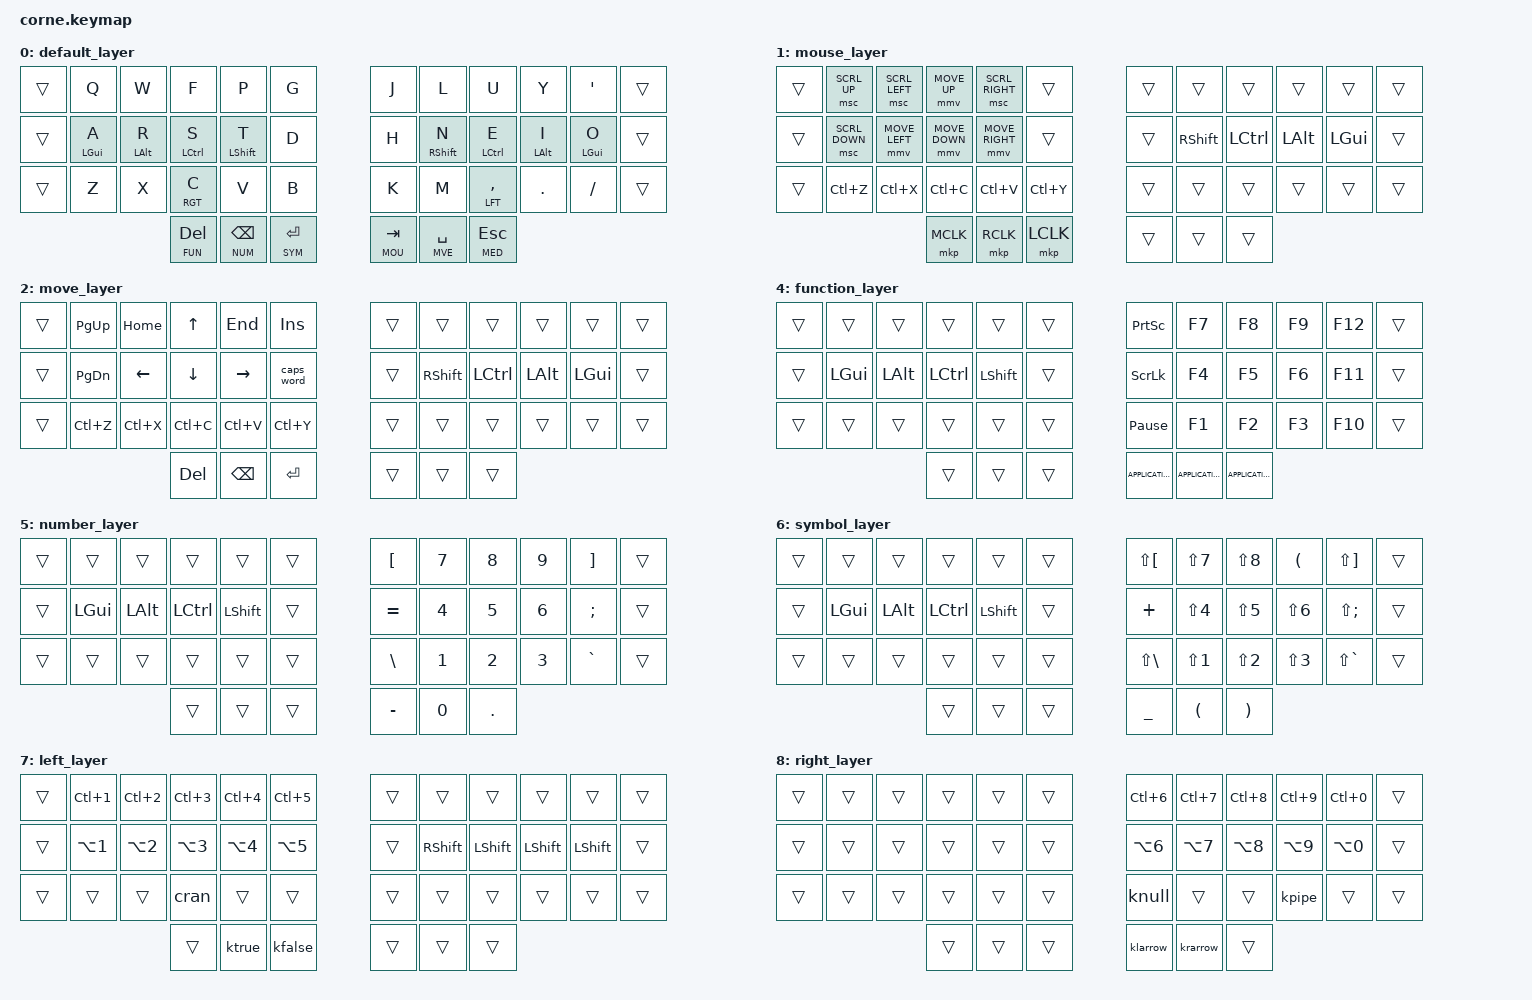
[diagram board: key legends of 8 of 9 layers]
#include <behaviors.dtsi>
#include <dt-bindings/zmk/keys.h>
#include <dt-bindings/zmk/bt.h>
#define _BT_SEL_KEYS_ &bt BT_SEL 0 &bt BT_SEL 1 &bt BT_SEL 2 &bt BT_SEL 3 &bt BT_CLR

#include <dt-bindings/zmk/mouse.h>

#include "../zmk-nodefree-config/helper.h"
#include "../zmk-nodefree-config/keypos_def/keypos_42keys.h"
//#include "../zmk-nodefree-config/international_chars/german.dtsi"

/* layer and key shortcuts */

#define XXX &none
#define ___ &trans

#define DEF 0 // layer shortcuts, must match order in which they are defined below
#define MOU 1 // mouse layer
#define MVE 2 // move layer
#define MED 3 // media layer
#define FUN 4 // function layer
#define NUM 5 // number layer
#define SYM 6 // symbols
#define LFT 7 // left extra
#define RGT 8 // right extra

/* custom behaviors */
// https://github.com/urob/zmk-config?tab=readme-ov-file#timeless-homerow-mods
#define KEYS_L LT0 LT1 LT2 LT3 LT4 LT5 LM0 LM1 LM2 LM3 LM4 LM5 LB0 LB1 LB2 LB3 LB4 LB5  // left-hand keys
#define KEYS_R RT0 RT1 RT2 RT3 RT4 RT5 RM0 RM1 RM2 RM3 RM4 RM5 RB0 RB1 RB2 RB3 RB4 RB5  // right-hand keys
#define THUMBS LH2 LH1 LH0 RH0 RH1 RH2                                      // thumb keys


// From https://github.com/urob/zmk-config/blob/main/config/mouse.dtsi
#define ZMK_MOUSE_DEFAULT_MOVE_VAL 1500  // 600
#define ZMK_MOUSE_DEFAULT_SCRL_VAL 20    // 10

&mmv {
  acceleration-exponent = <1>;      // 1
  time-to-max-speed-ms = <500>;    // 40
  delay-ms = <0>;                   // 0
};

&msc {
  acceleration-exponent = <1>;      // 0
  time-to-max-speed-ms = <40>;      // 500
  delay-ms = <0>;                   // 10
};

#define U_MS_U &mmv MOVE_UP
#define U_MS_D &mmv MOVE_DOWN
#define U_MS_L &mmv MOVE_LEFT
#define U_MS_R &mmv MOVE_RIGHT
#define U_WH_U &msc SCRL_UP
#define U_WH_D &msc SCRL_DOWN
#define U_WH_L &msc SCRL_LEFT
#define U_WH_R &msc SCRL_RIGHT

// #define U_MS_U &none
// #define U_MS_D &none
// #define U_MS_L &none
// #define U_MS_R &none
// #define U_WH_U &none
// #define U_WH_D &none
// #define U_WH_L &none
// #define U_WH_R &none

#define TAP_TERM_MS_SHIFT 200
#define TAP_TERM_MS_TIMERLESS 280
#define TAP_TERM_QUICK 150

/* left-hand HRMs */
ZMK_BEHAVIOR(hmls, hold_tap,
             flavor = "balanced";
             tapping-term-ms = <TAP_TERM_MS_SHIFT>;
             bindings = <&kp>, <&kp>;
             hold-trigger-key-positions = <KEYS_R THUMBS>;
             hold-trigger-on-release;             // delay positional check until key-release
             )

ZMK_BEHAVIOR(hml, hold_tap,
             flavor = "balanced";
             tapping-term-ms = <TAP_TERM_MS_TIMERLESS>;
             quick-tap-ms = <175>;                // repeat on tap-into-hold
             require-prior-idle-ms = <TAP_TERM_QUICK>;
             bindings = <&kp>, <&kp>;
             hold-trigger-key-positions = <KEYS_R THUMBS>;
             hold-trigger-on-release;             // delay positional check until key-release
             )

/* right-hand HRMs */
ZMK_BEHAVIOR(hmr, hold_tap,
             flavor = "balanced";
             tapping-term-ms = <TAP_TERM_MS_TIMERLESS>;
             quick-tap-ms = <175>;                // repeat on tap-into-hold
             require-prior-idle-ms = <TAP_TERM_QUICK>;
             bindings = <&kp>, <&kp>;
             hold-trigger-key-positions = <KEYS_L THUMBS>;
             hold-trigger-on-release;             // delay positional check until key-release
             )

ZMK_BEHAVIOR(hmrs, hold_tap,
             flavor = "balanced";
             tapping-term-ms = <TAP_TERM_MS_SHIFT>;
             bindings = <&kp>, <&kp>;
             hold-trigger-key-positions = <KEYS_L THUMBS>;
             hold-trigger-on-release;             // delay positional check until key-release
             )

// macros

ZMK_BEHAVIOR(cran, macro,
             wait-ms = <0>;
             tap-ms = <1>;
             bindings = <&macro_press &kp LSHFT>
                      , <&macro_tap &kp C &kp R &kp A &kp N>
                      , <&macro_release &kp LSHFT>
             ;)

ZMK_BEHAVIOR(ktrue, macro,
             wait-ms = <0>;
             tap-ms = <1>;
             bindings = <&macro_press &kp LSHFT>
             , <&macro_tap &kp T &kp R &kp U &kp E>
             , <&macro_release &kp LSHFT>
             ;)

ZMK_BEHAVIOR(kfalse, macro,
             wait-ms = <0>;
             tap-ms = <1>;
             bindings = <&macro_press &kp LSHFT>
             , <&macro_tap &kp F &kp A &kp L &kp S &kp E>
             , <&macro_release &kp LSHFT>
             ;)

ZMK_BEHAVIOR(knull, macro,
             wait-ms = <0>;
             tap-ms = <1>;
             bindings = <&macro_press &kp LSHFT>
             , <&macro_tap &kp N &kp U &kp L &kp L>
             , <&macro_release &kp LSHFT>
             ;)

ZMK_BEHAVIOR(kpipe, macro,
             wait-ms = <0>;
             tap-ms = <1>;
             bindings = <&macro_press &kp LSHFT>
             , <&macro_tap &kp N5 &kp DOT &kp N5>
             , <&macro_release &kp LSHFT>
             ;)

ZMK_BEHAVIOR(krpipe, macro,
             wait-ms = <0>;
             tap-ms = <1>;
             bindings = <&macro_press &kp LSHFT>
             , <&macro_tap &kp BSLH &kp DOT>
             , <&macro_release &kp LSHFT>
             ;)

ZMK_BEHAVIOR(krarrow, macro,
             wait-ms = <0>;
             tap-ms = <1>;
             bindings =
             <&macro_tap &kp MINUS>,
             <&macro_press &kp LSHFT>
             , <&macro_tap &kp DOT>
             , <&macro_release &kp LSHFT>
             ;)

ZMK_BEHAVIOR(klarrow, macro,
             wait-ms = <0>;
             tap-ms = <1>;
             bindings =
             <&macro_press &kp LSHFT>
             , <&macro_tap &kp COMMA>
             , <&macro_release &kp LSHFT>,
             <&macro_tap &kp MINUS>
             ;)

// smart mouse

#undef COMBO_HOOK
#define COMBO_HOOK require-prior-idle-ms = <150>;

#define COMBO_TERM_FAST 18
#define COMBO_TERM_SLOW 30


/*                                      42 KEY MATRIX / LAYOUT MAPPING

╭────────────────────────┬────────────────────────╮ ╭─────────────────────────┬─────────────────────────╮
│  0   1   2   3   4   5 │  6   7   8   9  10  11 │ │ LT5 LT4 LT3 LT2 LT1 LT0 │ RT0 RT1 RT2 RT3 RT4 RT5 │
│ 12  13  14  15  16  17 │ 18  19  20  21  22  23 │ │ LM5 LM4 LM3 LM2 LM1 LM0 │ RM0 RM1 RM2 RM3 RM4 RM5 │
│ 24  25  26  27  28  29 │ 30  31  32  33  34  35 │ │ LB5 LB4 LB3 LB2 LB1 LB0 │ RB0 RB1 RB2 RB3 RB4 RB5 │
╰───────────╮ 36  37  38 │ 39  40  41 ╭───────────╯ ╰───────────╮ LH2 LH1 LH0 │ RH0 RH1 RH2 ╭───────────╯
╰────────────┴────────────╯                         ╰─────────────┴─────────────╯             */


ZMK_BEHAVIOR(smart_mouse, tri_state,
             bindings = <&tog MOU>, <&none>, <&tog MOU>;
             ignored-key-positions = <LT4 LT3 LT2 LT1 LM4 LM3 LM2 LM1 LH2 LH1 LH0 RM1 RM2 RM3 RM4>;
             ignored-layers = <MOU>;
             )

ZMK_COMBO(mouse, &smart_mouse,  LT3 LT1,    DEF MVE MED FUN NUM SYM LFT RGT, COMBO_TERM_FAST)
ZMK_COMBO(mouseOff, &to MOU, LT3 LT1, MOU, COMBO_TERM_FAST)

ZMK_COMBO(menuAltEqual, &kp LA(EQUAL), LB4 LB3, ALL, COMBO_TERM_FAST)

/* keymap */

ZMK_LAYER(default_layer,
     // ╭─────────────┬─────────────┬─────────────┬─────────────┬─────────────╮   ╭─────────────┬─────────────┬─────────────┬─────────────┬─────────────╮
___       &kp Q         &kp W         &kp F         &kp P         &kp G             &kp J         &kp L         &kp U         &kp Y         &kp SQT      ___
     // ├─────────────┼─────────────┼─────────────┼─────────────┼─────────────┤   ├─────────────┼─────────────┼─────────────┼─────────────┼─────────────┤
___       &hml LGUI A   &hml LALT R   &hml LCTRL S &hmls LSHFT T  &kp D             &kp H         &hmrs RSHFT N  &hmr LCTRL E &hmr LALT I   &hmr LGUI O    ___
     // ├─────────────┼─────────────┼─────────────┼─────────────┼─────────────┤   ├─────────────┼─────────────┼─────────────┼─────────────┼─────────────┤
___       &kp Z         &kp X        &lt RGT C         &kp V         &kp B             &kp K         &kp M        &lt LFT COMMA  &kp DOT       &kp SLASH      ___
     // ╰─────────────┼─────────────┼─────────────┼─────────────┼─────────────┤   ├─────────────┼─────────────┼─────────────┼─────────────┼─────────────┤
                                     &lt FUN DEL   &lt NUM BSPC  &lt SYM RET       &lt MOU TAB   &lt MVE SPACE &lt MED ESC
     //                             ╰─────────────┴─────────────┴─────────────╯   ╰─────────────┴─────────────┴─────────────╯
)
ZMK_LAYER(mouse_layer,
     // ╭─────────────┬─────────────┬─────────────┬─────────────┬─────────────╮   ╭─────────────┬─────────────┬─────────────┬─────────────┬─────────────╮
___       U_WH_U       U_WH_L        U_MS_U       U_WH_R        ___               ___            ___           ___          ___           ___           ___
     // ├─────────────┼─────────────┼─────────────┼─────────────┼─────────────┤   ├─────────────┼─────────────┼─────────────┼─────────────┼─────────────┤
___       U_WH_D       U_MS_L       U_MS_D        U_MS_R        ___               ___           &kp RSHFT     &kp LCTRL     &kp LALT      &kp LGUI      ___
     // ├─────────────┼─────────────┼─────────────┼─────────────┼─────────────┤   ├─────────────┼─────────────┼─────────────┼─────────────┼─────────────┤
___       &kp LC(Z)    &kp LC(X)    &kp LC(C)      &kp LC(V)     &kp LC(Y)         ___           ___           ___          ___           ___            ___
     // ╰─────────────┼─────────────┼─────────────┼─────────────┼─────────────┤   ├─────────────┼─────────────┼─────────────┼─────────────┼─────────────┤
                                     &mkp MCLK     &mkp RCLK     &mkp LCLK         ___           ___           ___
     //                             ╰─────────────┴─────────────┴─────────────╯   ╰─────────────┴─────────────┴─────────────╯
)

ZMK_LAYER(move_layer,
     // ╭─────────────┬─────────────┬─────────────┬─────────────┬─────────────╮   ╭─────────────┬─────────────┬─────────────┬─────────────┬─────────────╮
___       &kp PG_UP    &kp HOME      &kp UP        &kp END       &kp INS            ___            ___           ___          ___           ___         ___
     // ├─────────────┼─────────────┼─────────────┼─────────────┼─────────────┤   ├─────────────┼─────────────┼─────────────┼─────────────┼─────────────┤
___       &kp PG_DN   &kp LEFT      &kp DOWN      &kp RIGHT     &caps_word         ___           &kp RSHFT     &kp LCTRL     &kp LALT      &kp LGUI     ___
     // ├─────────────┼─────────────┼─────────────┼─────────────┼─────────────┤   ├─────────────┼─────────────┼─────────────┼─────────────┼─────────────┤
___       &kp LC(Z)    &kp LC(X)    &kp LC(C)      &kp LC(V)     &kp LC(Y)         ___           ___           ___          ___           ___           ___
     // ╰─────────────┼─────────────┼─────────────┼─────────────┼─────────────┤   ├─────────────┼─────────────┼─────────────┼─────────────┼─────────────┤
                                     &kp DEL       &kp BSPC      &kp RET            ___           ___           ___
     //                             ╰─────────────┴─────────────┴─────────────╯   ╰─────────────┴─────────────┴─────────────╯
)

ZMK_LAYER(media_layer,
     // ╭─────────────┬─────────────┬─────────────┬─────────────┬─────────────╮   ╭─────────────┬─────────────┬─────────────┬─────────────┬─────────────╮
___       ___           &kp C_BRI_DN &kp C_VOL_UP  &kp C_BRI_UP  &bootloader       &bootloader    ___           ___           ___           ___           ___
     // ├─────────────┼─────────────┼─────────────┼─────────────┼─────────────┤   ├─────────────┼─────────────┼─────────────┼─────────────┼─────────────┤
___       ___          &kp C_PREV   &kp C_VOL_DN   &kp C_NEXT   &sys_reset        &sys_reset     &kp RSHFT     &kp LCTRL     &kp LALT      &kp LGUI     ___
     // ├─────────────┼─────────────┼─────────────┼─────────────┼─────────────┤   ├─────────────┼─────────────┼─────────────┼─────────────┼─────────────┤
          ___        _BT_SEL_KEYS_                                                ___           ___           ___          ___           ___           ___
     // ╰─────────────┼─────────────┼─────────────┼─────────────┼─────────────┤   ├─────────────┼─────────────┼─────────────┼─────────────┼─────────────┤
                                     &kp C_MUTE   &kp C_PP      &kp C_STOP         ___           ___           ___
     //                             ╰─────────────┴─────────────┴─────────────╯   ╰─────────────┴─────────────┴─────────────╯
)


ZMK_LAYER(function_layer,
     // ╭─────────────┬─────────────┬─────────────┬─────────────┬─────────────╮   ╭─────────────┬─────────────┬─────────────┬─────────────┬─────────────╮
___       ___          ___           ___           ___           ___                &kp PSCRN    &kp F7        &kp F8        &kp F9        &kp F12     ___
     // ├─────────────┼─────────────┼─────────────┼─────────────┼─────────────┤   ├─────────────┼─────────────┼─────────────┼─────────────┼─────────────┤
___      &kp LGUI     &kp LALT      &kp LCTL      &kp LSHFT     ___                &kp SLCK     &kp F4        &kp F5        &kp F6         &kp F11      ___
     // ├─────────────┼─────────────┼─────────────┼─────────────┼─────────────┤   ├─────────────┼─────────────┼─────────────┼─────────────┼─────────────┤
___       ___          ___           ___           ___           ___             &kp PAUSE_BREAK &kp F1        &kp F2       &kp F3         &kp F10      ___
     // ╰─────────────┼─────────────┼─────────────┼─────────────┼─────────────┤   ├─────────────┼─────────────┼─────────────┼─────────────┼─────────────┤
                                      ___          ___           ___           &kp K_APPLICATION &kp K_APPLICATION &kp K_APPLICATION
     //                             ╰─────────────┴─────────────┴─────────────╯   ╰─────────────┴─────────────┴─────────────╯
)

ZMK_LAYER(number_layer,
     // ╭─────────────┬─────────────┬─────────────┬─────────────┬─────────────╮   ╭─────────────┬─────────────┬─────────────┬─────────────┬─────────────╮
___       ___          ___           ___           ___           ___                &kp LBKT    &kp N7        &kp N8        &kp N9        &kp RBKT      ___
     // ├─────────────┼─────────────┼─────────────┼─────────────┼─────────────┤   ├─────────────┼─────────────┼─────────────┼─────────────┼─────────────┤
___      &kp LGUI     &kp LALT      &kp LCTL      &kp LSHFT     ___                &kp EQUAL    &kp N4        &kp N5        &kp N6        &kp SEMI      ___
     // ├─────────────┼─────────────┼─────────────┼─────────────┼─────────────┤   ├─────────────┼─────────────┼─────────────┼─────────────┼─────────────┤
___       ___          ___           ___           ___           ___               &kp BSLH      &kp N1       &kp N2         &kp N3       &kp GRAVE     ___
     // ╰─────────────┼─────────────┼─────────────┼─────────────┼─────────────┤   ├─────────────┼─────────────┼─────────────┼─────────────┼─────────────┤
                                      ___          ___           ___                &kp MINUS     &kp N0      &kp DOT
     //                             ╰─────────────┴─────────────┴─────────────╯   ╰─────────────┴─────────────┴─────────────╯
)

ZMK_LAYER(symbol_layer,
     // ╭─────────────┬─────────────┬─────────────┬─────────────┬─────────────╮   ╭─────────────┬─────────────┬─────────────┬─────────────┬─────────────╮
___       ___          ___           ___           ___           ___              &kp LS(LBKT)   &kp LS(N7)    &kp LS(N8)   &kp LPAR      &kp LS(RBKT)  ___
     // ├─────────────┼─────────────┼─────────────┼─────────────┼─────────────┤   ├─────────────┼─────────────┼─────────────┼─────────────┼─────────────┤
___       &kp LGUI     &kp LALT      &kp LCTL      &kp LSHFT      ___            &kp PLUS       &kp LS(N4)    &kp LS(N5)    &kp LS(N6)   &kp LS(SEMI)   ___
     // ├─────────────┼─────────────┼─────────────┼─────────────┼─────────────┤   ├─────────────┼─────────────┼─────────────┼─────────────┼─────────────┤
___       ___          ___           ___           ___           ___               &kp LS(BSLH)  &kp LS(N1)    &kp LS(N2)    &kp LS(N3)   &kp LS(GRAVE) ___
     // ╰─────────────┼─────────────┼─────────────┼─────────────┼─────────────┤   ├─────────────┼─────────────┼─────────────┼─────────────┼─────────────┤
                                         ___          ___           ___               &kp UNDER   &kp LPAR   &kp RPAR
     //                             ╰─────────────┴─────────────┴─────────────╯   ╰─────────────┴─────────────┴─────────────╯
)

ZMK_LAYER(left_layer,
      // ╭─────────────┬─────────────┬─────────────┬─────────────┬─────────────╮   ╭─────────────┬─────────────┬─────────────┬─────────────┬─────────────╮
___      &kp LC(N1)     &kp LC(N2)    &kp LC(N3)    &kp LC(N4)    &kp LC(N5)        ___          ___           ___           ___           ___           ___
      // ├─────────────┼─────────────┼─────────────┼─────────────┼─────────────┤   ├─────────────┼─────────────┼─────────────┼─────────────┼─────────────┤
___      &kp LA(N1)    &kp LA(N2)    &kp LA(N3)    &kp LA(N4)     &kp LA(N5)        ___            &kp RSHFT     &kp LSHFT     &kp LSHFT     &kp LSHFT    ___
      // ├─────────────┼─────────────┼─────────────┼─────────────┼─────────────┤   ├─────────────┼─────────────┼─────────────┼─────────────┼─────────────┤
___       ___          ___           &cran          ___            ___              ___           ___          ___           ___            ___             ___
      // ╰─────────────┼─────────────┼─────────────┼─────────────┼─────────────┤   ├─────────────┼─────────────┼─────────────┼─────────────┼─────────────┤
                                       ___           &ktrue        &kfalse           ___           ___           ___
       //                             ╰─────────────┴─────────────┴─────────────╯   ╰─────────────┴─────────────┴─────────────╯
          )


ZMK_LAYER(right_layer,
          // ╭─────────────┬─────────────┬─────────────┬─────────────┬─────────────╮   ╭─────────────┬─────────────┬─────────────┬─────────────┬─────────────╮
___           ___          ___            ___          ___           ___                 &kp LC(N6)   &kp LC(N7)   &kp LC(N8)     &kp LC(N9)    &kp LC(N0)    ___
          // ├─────────────┼─────────────┼─────────────┼─────────────┼─────────────┤   ├─────────────┼─────────────┼─────────────┼─────────────┼─────────────┤
___           ___          ___           ___           ___            ___               &kp LA(N6)   &kp LA(N7)    &kp LA(N8)    &kp LA(N9)    &kp LA(N0)     ___
          // ├─────────────┼─────────────┼─────────────┼─────────────┼─────────────┤   ├─────────────┼─────────────┼─────────────┼─────────────┼─────────────┤
___           ___          ___           ___           ___            ___               &knull       ___          ___            &kpipe            ___             ___
          // ╰─────────────┼─────────────┼─────────────┼─────────────┼─────────────┤   ├─────────────┼─────────────┼─────────────┼─────────────┼─────────────┤
                                          ___           ___           ___                &klarrow     &krarrow           ___
          //                             ╰─────────────┴─────────────┴─────────────╯   ╰─────────────┴─────────────┴─────────────╯
          )
